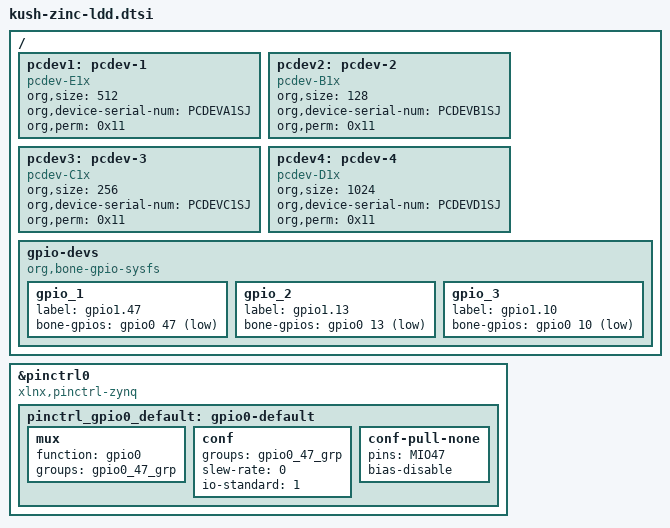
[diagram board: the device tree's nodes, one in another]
/ {
	pcdev1: pcdev-1 {  
        	compatible = "pcdev-E1x","pcdev-A1x";
		org,size = <512>;
		org,device-serial-num = "PCDEVA1SJ";
		org,perm = <0x11>;
	};

	pcdev2: pcdev-2 {
        	compatible = "pcdev-B1x";
		org,size = <128>;
        	org,device-serial-num = "PCDEVB1SJ";
		org,perm = <0x11>;
	};
       	
        pcdev3: pcdev-3 {
        	compatible = "pcdev-C1x";
		org,size = <256>;
        	org,device-serial-num = "PCDEVC1SJ";
		org,perm = <0x11>;
	};

        pcdev4: pcdev-4 {
        	compatible = "pcdev-D1x";
		org,size = <1024>;
        	org,device-serial-num = "PCDEVD1SJ";
		org,perm = <0x11>;
	};

   gpio-devs
   {
      compatible = "org,bone-gpio-sysfs";

	  gpio_1 {
        label="gpio1.47"; 
		bone-gpios=<&gpio0 47 1>;  /*usr led */
	  };

      gpio_2 {
        label="gpio1.13";
		bone-gpios = <&gpio0 13 1>;
	  };

	  gpio_3 {
        label="gpio1.10";
		bone-gpios=<&gpio0 10 1>;
	  };

   };

};

&pinctrl0 {
	  compatible = "xlnx,pinctrl-zynq";
	  pinctrl-names = "default";
	  pinctrl_gpio0_default: gpio0-default {
      
	  mux {

		  function = "gpio0";
		  groups = "gpio0_47_grp";
	  };

	  conf {
          groups = "gpio0_47_grp";
		  slew-rate = <0>;
		  io-standard = <1>;
	  };

	  conf-pull-none{
		  pins = "MIO47";
		  bias-disable;
	  };

	};
};
        








       






